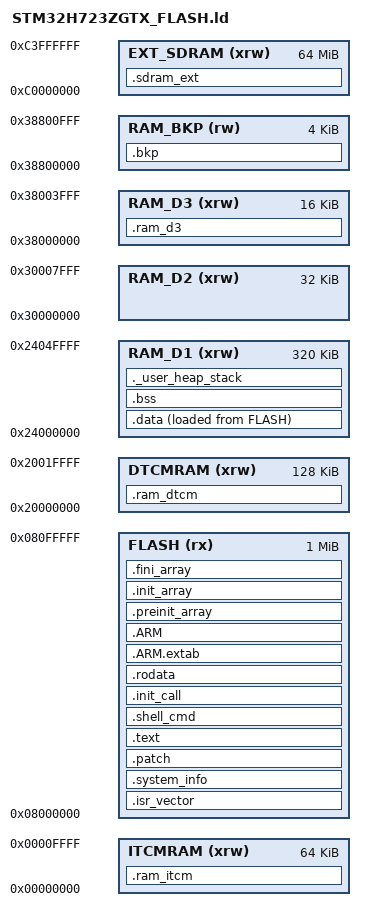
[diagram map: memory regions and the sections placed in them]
/*
******************************************************************************
**
**  File        : LinkerScript.ld
**
**  Author      : STM32CubeIDE
**
**  Abstract    : Linker script for STM32H7 series
**                1024Kbytes FLASH and 560Kbytes RAM
**
**                Set heap size, stack size and stack location according
**                to application requirements.
**
**                Set memory bank area and size if external memory is used.
**
**  Target      : STMicroelectronics STM32
**
**  Distribution: The file is distributed as is, without any warranty
**                of any kind.
**
*****************************************************************************
** @attention
**
** Copyright (c) 2025 STMicroelectronics.
** All rights reserved.
**
** This software is licensed under terms that can be found in the LICENSE file
** in the root directory of this software component.
** If no LICENSE file comes with this software, it is provided AS-IS.
**
****************************************************************************
*/

/* Entry Point */
ENTRY(Reset_Handler)

/* Highest address of the user mode stack */
_estack = ORIGIN(RAM_D1) + LENGTH(RAM_D1);    /* end of RAM */
/* Generate a link error if heap and stack don't fit into RAM */
_Min_Heap_Size = 0x1000;      /* required amount of heap  */
_Min_Stack_Size = 0x1000; /* required amount of stack */

/* Specify the memory areas */
MEMORY
{
  ITCMRAM (xrw)    : ORIGIN = 0x00000000,   LENGTH = 64K
  DTCMRAM (xrw)    : ORIGIN = 0x20000000,   LENGTH = 128K
  FLASH    (rx)    : ORIGIN = 0x08000000,   LENGTH = 1024K
  RAM_D1  (xrw)    : ORIGIN = 0x24000000,   LENGTH = 320K
  RAM_D2  (xrw)    : ORIGIN = 0x30000000,   LENGTH = 32K
  RAM_D3  (xrw)    : ORIGIN = 0x38000000,   LENGTH = 16K
  RAM_BKP  (rw)    : ORIGIN = 0x38800000,   LENGTH = 4K
  EXT_SDRAM (xrw)  : ORIGIN = 0xC0000000,   LENGTH = 64M
}

/* Define output sections */
SECTIONS
{
  /* The startup code goes first into FLASH */
  .isr_vector :
  {
    . = ALIGN(4);
    __isr_vector_start = .;
    KEEP(*(.isr_vector)) /* Startup code */
    . = ALIGN(4);
  } >FLASH

  .system_info :
  {
    . = ORIGIN(FLASH) + 0x400;
    __system_info_start = .;
    KEEP(*(.system_info*))
    __system_info_end = .;
  } >FLASH

  .patch :
  {
    /* patch for bootloader, which will be executed before jump judgement */
    . = ORIGIN(FLASH) + 0x800;
    . = ALIGN(4);
    __patch_table_start = .;
    KEEP(*(.patch_functions_1))
    . = ALIGN(0x400);
    KEEP(*(.patch_functions_2))
    . = ALIGN(0x400);
    KEEP(*(.patch_functions_3))
    . = ALIGN(0x400);
    KEEP(*(.patch_functions_4))
    __patch_table_end = .;
  } >FLASH

  /* The program code and other data goes into FLASH */
  .text :
  {
    . = ALIGN(4);
    _stext = .;

    *(.text)           /* .text sections (code) */
    *(.text*)          /* .text* sections (code) */
    *(.glue_7)         /* glue arm to thumb code */
    *(.glue_7t)        /* glue thumb to arm code */
    *(.eh_frame)

    KEEP (*(.init))
    KEEP (*(.fini))

    . = ALIGN(4);
    _etext = .;        /* define a global symbols at end of code */
  } >FLASH

  .shell_cmd :
  {
    . = ALIGN(4);
    __shell_cmd_start = .;
    KEEP(*(SORT(.shell_cmd_fn*)))
    __shell_cmd_end = .;
  } >FLASH

  .init_call :
  {
    . = ALIGN(4);
    __init_call_start = .;
    KEEP(*(SORT(.init_call_fn*)))
    __init_call_end = .;

  } >FLASH

  /* Constant data goes into FLASH */
  .rodata :
  {
    . = ALIGN(4);
    *(.rodata)         /* .rodata sections (constants, strings, etc.) */
    *(.rodata*)        /* .rodata* sections (constants, strings, etc.) */
    . = ALIGN(4);
  } >FLASH

  .ARM.extab (READONLY) : /* The READONLY keyword is only supported in GCC11 and later, remove it if using GCC10 or earlier. */
  {
    *(.ARM.extab* .gnu.linkonce.armextab.*)
  } >FLASH
  .ARM (READONLY) : /* The READONLY keyword is only supported in GCC11 and later, remove it if using GCC10 or earlier. */
  {
    __exidx_start = .;
    *(.ARM.exidx*)
    __exidx_end = .;
  } >FLASH

  .preinit_array (READONLY) : /* The READONLY keyword is only supported in GCC11 and later, remove it if using GCC10 or earlier. */
  {
    PROVIDE_HIDDEN (__preinit_array_start = .);
    KEEP (*(.preinit_array*))
    PROVIDE_HIDDEN (__preinit_array_end = .);
  } >FLASH

  .init_array (READONLY) : /* The READONLY keyword is only supported in GCC11 and later, remove it if using GCC10 or earlier. */
  {
    PROVIDE_HIDDEN (__init_array_start = .);
    KEEP (*(SORT(.init_array.*)))
    KEEP (*(.init_array*))
    PROVIDE_HIDDEN (__init_array_end = .);
  } >FLASH

  .fini_array (READONLY) : /* The READONLY keyword is only supported in GCC11 and later, remove it if using GCC10 or earlier. */
  {
    PROVIDE_HIDDEN (__fini_array_start = .);
    KEEP (*(SORT(.fini_array.*)))
    KEEP (*(.fini_array*))
    PROVIDE_HIDDEN (__fini_array_end = .);
  } >FLASH

  /* used by the startup to initialize data */
  _sidata = LOADADDR(.data);

  /* Initialized data sections goes into RAM, load LMA copy after code */
  .data :
  {
    . = ALIGN(4);
    _sdata = .;        /* create a global symbol at data start */
    *(.data)           /* .data sections */
    *(.data*)          /* .data* sections */
    *(.RamFunc)        /* .RamFunc sections */
    *(.RamFunc*)       /* .RamFunc* sections */

    . = ALIGN(4);
    _edata = .;        /* define a global symbol at data end */
  } >RAM_D1 AT> FLASH

  /* Uninitialized data section */
  . = ALIGN(4);
  .bss :
  {
    /* This is used by the startup in order to initialize the .bss section */
    _sbss = .;         /* define a global symbol at bss start */
    __bss_start__ = _sbss;
    *(.bss)
    *(.bss*)
    *(COMMON)

    . = ALIGN(4);
    _ebss = .;         /* define a global symbol at bss end */
    __bss_end__ = _ebss;
  } >RAM_D1

  /* User_heap_stack section, used to check that there is enough RAM left */
  ._user_heap_stack :
  {
    . = ALIGN(8);
    PROVIDE ( end = . );
    PROVIDE ( _end = . );
    . = . + _Min_Heap_Size;
    _sstack = .;
    . = . + _Min_Stack_Size;
    . = ALIGN(8);
  } >RAM_D1

  .bkp (NOLOAD) :
  {
    . = ALIGN(4);
    _bkp_start_ = .;

    KEEP(*(.bkp*))
  } >RAM_BKP

  .ram_d3 (NOLOAD) :
  {
    . = ALIGN(4);
    KEEP(*(.ram_d3))
  } >RAM_D3

  .ram_itcm (NOLOAD) :
  {
    . = ALIGN(4);
    KEEP(*(.ram_itcm))
  } >ITCMRAM

  .ram_dtcm (NOLOAD) :
  {
    . = ALIGN(4);
    KEEP(*(.ram_dtcm))
  } >DTCMRAM

  .sdram_ext (NOLOAD) :
  {
    . = ALIGN(4);
    KEEP(*(.sdram_ext))
  } >EXT_SDRAM
  
  /* Remove information from the standard libraries */
  /DISCARD/ :
  {
    libc.a ( * )
    libm.a ( * )
    libgcc.a ( * )
  }

  .ARM.attributes 0 : { *(.ARM.attributes) }
}
